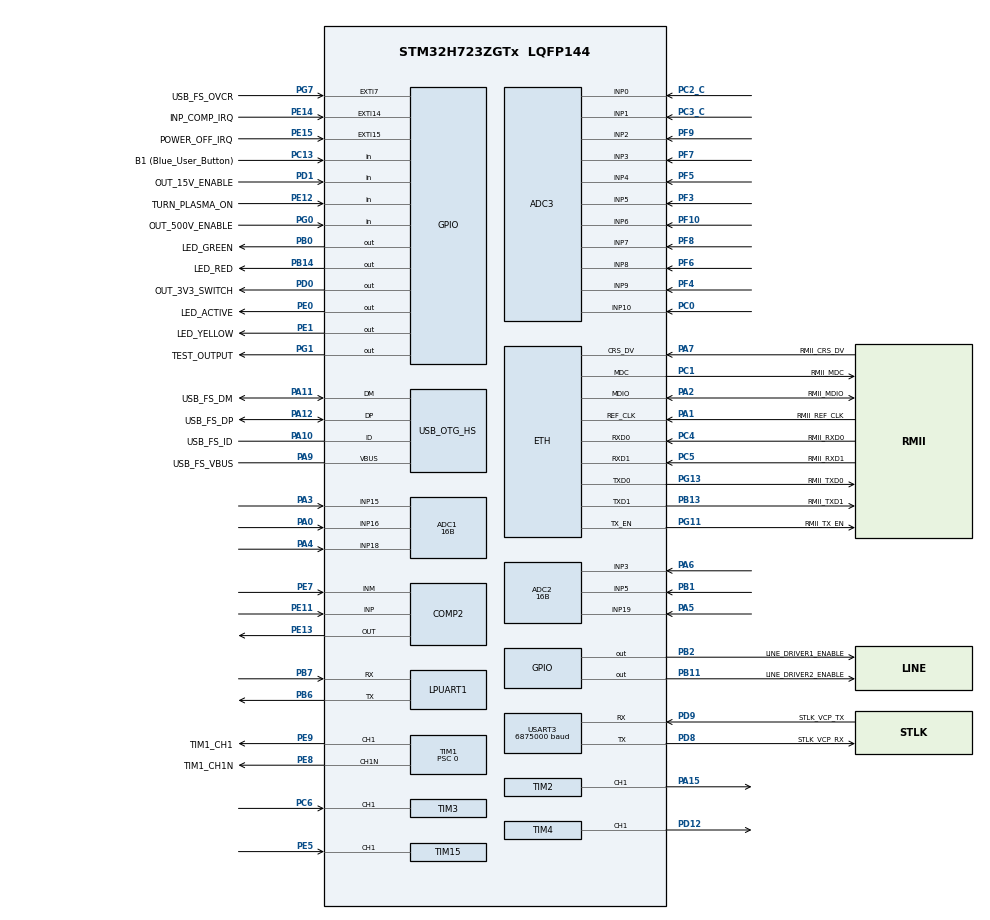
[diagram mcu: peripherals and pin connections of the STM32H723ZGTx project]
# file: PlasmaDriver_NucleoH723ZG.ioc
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ADC1.Channel-11\#ChannelRegularConversion=ADC_CHANNEL_16
ADC1.Channel-6\#ChannelRegularConversion=ADC_CHANNEL_15
ADC1.Channel-7\#ChannelRegularConversion=ADC_CHANNEL_18
ADC1.ContinuousConvMode=ENABLE
ADC1.ConversionDataManagement=ADC_CONVERSIONDATA_DMA_ONESHOT
ADC1.DMAAccessModeView=ENABLE
ADC1.DiscontinuousConvMode=DISABLE
ADC1.EOCSelection=ADC_EOC_SEQ_CONV
ADC1.ExternalTrigConv=ADC_EXTERNALTRIG_T1_CC1
ADC1.LowPowerAutoWait=DISABLE
ADC1.Mode=ADC_DUALMODE_REGSIMULT
ADC1.NbrOfConversion=3
ADC1.NbrOfConversionFlag=1
ADC1.OffsetNumber-11\#ChannelRegularConversion=ADC_OFFSET_NONE
ADC1.OffsetNumber-6\#ChannelRegularConversion=ADC_OFFSET_NONE
ADC1.OffsetNumber-7\#ChannelRegularConversion=ADC_OFFSET_NONE
ADC1.OffsetSignedSaturation-11\#ChannelRegularConversion=DISABLE
ADC1.OffsetSignedSaturation-6\#ChannelRegularConversion=DISABLE
ADC1.OffsetSignedSaturation-7\#ChannelRegularConversion=DISABLE
ADC1.Rank-11\#ChannelRegularConversion=3
ADC1.Rank-6\#ChannelRegularConversion=1
ADC1.Rank-7\#ChannelRegularConversion=2
ADC1.Resolution=ADC_RESOLUTION_16B
ADC1.SamplingTime-11\#ChannelRegularConversion=ADC_SAMPLETIME_8CYCLES_5
ADC1.SamplingTime-6\#ChannelRegularConversion=ADC_SAMPLETIME_8CYCLES_5
ADC1.SamplingTime-7\#ChannelRegularConversion=ADC_SAMPLETIME_8CYCLES_5
ADC1.TwoSamplingDelay=ADC_TWOSAMPLINGDELAY_1CYCLE
ADC1.master=1
ADC2.Channel-0\#ChannelRegularConversion=ADC_CHANNEL_3
ADC2.Channel-1\#ChannelRegularConversion=ADC_CHANNEL_19
ADC2.Channel-3\#ChannelRegularConversion=ADC_CHANNEL_5
ADC2.ClockPrescaler=ADC_CLOCK_ASYNC_DIV1
ADC2.ContinuousConvMode=ENABLE
ADC2.ConversionDataManagement=ADC_CONVERSIONDATA_DR
ADC2.DMAAccessModeView=ENABLE
ADC2.EOCSelection=ADC_EOC_SEQ_CONV
ADC2.EnableAnalogWatchDog1=true
ADC2.Mode=ADC_DUALMODE_REGSIMULT
ADC2.NbrOfConversion=3
ADC2.NbrOfConversionFlag=1
ADC2.OffsetNumber-0\#ChannelRegularConversion=ADC_OFFSET_NONE
ADC2.OffsetNumber-1\#ChannelRegularConversion=ADC_OFFSET_NONE
ADC2.OffsetNumber-3\#ChannelRegularConversion=ADC_OFFSET_NONE
ADC2.OffsetSignedSaturation-0\#ChannelRegularConversion=DISABLE
ADC2.OffsetSignedSaturation-1\#ChannelRegularConversion=DISABLE
ADC2.OffsetSignedSaturation-3\#ChannelRegularConversion=DISABLE
ADC2.Rank-0\#ChannelRegularConversion=1
ADC2.Rank-1\#ChannelRegularConversion=2
ADC2.Rank-3\#ChannelRegularConversion=3
ADC2.Resolution=ADC_RESOLUTION_16B
ADC2.SamplingTime-0\#ChannelRegularConversion=ADC_SAMPLETIME_8CYCLES_5
ADC2.SamplingTime-1\#ChannelRegularConversion=ADC_SAMPLETIME_8CYCLES_5
ADC2.SamplingTime-3\#ChannelRegularConversion=ADC_SAMPLETIME_8CYCLES_5
ADC2.WatchdogChannel=ADC_CHANNEL_3
ADC3.Channel-0\#ChannelRegularConversion=ADC_CHANNEL_0
ADC3.Channel-1\#ChannelRegularConversion=ADC_CHANNEL_1
ADC3.Channel-11\#ChannelRegularConversion=ADC_CHANNEL_10
ADC3.Channel-2\#ChannelRegularConversion=ADC_CHANNEL_2
ADC3.Channel-3\#ChannelRegularConversion=ADC_CHANNEL_3
ADC3.Channel-4\#ChannelRegularConversion=ADC_CHANNEL_4
ADC3.Channel-5\#ChannelRegularConversion=ADC_CHANNEL_5
ADC3.Channel-6\#ChannelRegularConversion=ADC_CHANNEL_6
ADC3.Channel-7\#ChannelRegularConversion=ADC_CHANNEL_7
ADC3.Channel-8\#ChannelRegularConversion=ADC_CHANNEL_8
ADC3.Channel-9\#ChannelRegularConversion=ADC_CHANNEL_9
ADC3.ClockPrescaler=ADC_CLOCK_ASYNC_DIV1
ADC3.ContinuousConvMode=DISABLE
ADC3.ConversionDataManagement=ADC_CONVERSIONDATA_DMA_ONESHOT
ADC3.DMAContinuousRequests=ENABLE
ADC3.EOCSelection=ADC_EOC_SEQ_CONV
ADC3.Mode=ADC_DUALMODE_REGSIMULT
ADC3.NbrOfConversion=11
ADC3.NbrOfConversionFlag=1
ADC3.OffsetNumber-0\#ChannelRegularConversion=ADC_OFFSET_NONE
ADC3.OffsetNumber-1\#ChannelRegularConversion=ADC_OFFSET_NONE
ADC3.OffsetNumber-11\#ChannelRegularConversion=ADC_OFFSET_NONE
ADC3.OffsetNumber-2\#ChannelRegularConversion=ADC_OFFSET_NONE
ADC3.OffsetNumber-3\#ChannelRegularConversion=ADC_OFFSET_NONE
ADC3.OffsetNumber-4\#ChannelRegularConversion=ADC_OFFSET_NONE
ADC3.OffsetNumber-5\#ChannelRegularConversion=ADC_OFFSET_NONE
ADC3.OffsetNumber-6\#ChannelRegularConversion=ADC_OFFSET_NONE
ADC3.OffsetNumber-7\#ChannelRegularConversion=ADC_OFFSET_NONE
ADC3.OffsetNumber-8\#ChannelRegularConversion=ADC_OFFSET_NONE
ADC3.OffsetNumber-9\#ChannelRegularConversion=ADC_OFFSET_NONE
ADC3.OffsetSign-0\#ChannelRegularConversion=ADC3_OFFSET_SIGN_NEGATIVE
ADC3.OffsetSign-1\#ChannelRegularConversion=ADC3_OFFSET_SIGN_NEGATIVE
ADC3.OffsetSign-11\#ChannelRegularConversion=ADC3_OFFSET_SIGN_NEGATIVE
ADC3.OffsetSign-2\#ChannelRegularConversion=ADC3_OFFSET_SIGN_NEGATIVE
ADC3.OffsetSign-3\#ChannelRegularConversion=ADC3_OFFSET_SIGN_NEGATIVE
ADC3.OffsetSign-4\#ChannelRegularConversion=ADC3_OFFSET_SIGN_NEGATIVE
ADC3.OffsetSign-5\#ChannelRegularConversion=ADC3_OFFSET_SIGN_NEGATIVE
ADC3.OffsetSign-6\#ChannelRegularConversion=ADC3_OFFSET_SIGN_NEGATIVE
ADC3.OffsetSign-7\#ChannelRegularConversion=ADC3_OFFSET_SIGN_NEGATIVE
ADC3.OffsetSign-8\#ChannelRegularConversion=ADC3_OFFSET_SIGN_NEGATIVE
ADC3.OffsetSign-9\#ChannelRegularConversion=ADC3_OFFSET_SIGN_NEGATIVE
ADC3.Rank-0\#ChannelRegularConversion=1
ADC3.Rank-1\#ChannelRegularConversion=2
ADC3.Rank-11\#ChannelRegularConversion=11
ADC3.Rank-2\#ChannelRegularConversion=3
ADC3.Rank-3\#ChannelRegularConversion=4
ADC3.Rank-4\#ChannelRegularConversion=5
ADC3.Rank-5\#ChannelRegularConversion=6
ADC3.Rank-6\#ChannelRegularConversion=7
ADC3.Rank-7\#ChannelRegularConversion=8
ADC3.Rank-8\#ChannelRegularConversion=9
ADC3.Rank-9\#ChannelRegularConversion=10
ADC3.SamplingTime-0\#ChannelRegularConversion=ADC3_SAMPLETIME_6CYCLES_5
ADC3.SamplingTime-1\#ChannelRegularConversion=ADC3_SAMPLETIME_6CYCLES_5
ADC3.SamplingTime-11\#ChannelRegularConversion=ADC3_SAMPLETIME_6CYCLES_5
ADC3.SamplingTime-2\#ChannelRegularConversion=ADC3_SAMPLETIME_6CYCLES_5
ADC3.SamplingTime-3\#ChannelRegularConversion=ADC3_SAMPLETIME_6CYCLES_5
ADC3.SamplingTime-4\#ChannelRegularConversion=ADC3_SAMPLETIME_6CYCLES_5
ADC3.SamplingTime-5\#ChannelRegularConversion=ADC3_SAMPLETIME_6CYCLES_5
ADC3.SamplingTime-6\#ChannelRegularConversion=ADC3_SAMPLETIME_6CYCLES_5
ADC3.SamplingTime-7\#ChannelRegularConversion=ADC3_SAMPLETIME_6CYCLES_5
ADC3.SamplingTime-8\#ChannelRegularConversion=ADC3_SAMPLETIME_6CYCLES_5
ADC3.SamplingTime-9\#ChannelRegularConversion=ADC3_SAMPLETIME_6CYCLES_5
CORTEX_M7.CPU_DCache=Disabled
CORTEX_M7.CPU_ICache=Disabled
Dma.ADC1.1.Direction=DMA_PERIPH_TO_MEMORY
Dma.ADC1.1.EventEnable=DISABLE
Dma.ADC1.1.FIFOMode=DMA_FIFOMODE_DISABLE
Dma.ADC1.1.Instance=DMA1_Stream2
Dma.ADC1.1.MemDataAlignment=DMA_MDATAALIGN_WORD
Dma.ADC1.1.MemInc=DMA_MINC_ENABLE
Dma.ADC1.1.Mode=DMA_NORMAL
Dma.ADC1.1.PeriphDataAlignment=DMA_PDATAALIGN_WORD
Dma.ADC1.1.PeriphInc=DMA_PINC_DISABLE
Dma.ADC1.1.Polarity=HAL_DMAMUX_REQ_GEN_RISING
Dma.ADC1.1.Priority=DMA_PRIORITY_HIGH
Dma.ADC1.1.RequestNumber=1
Dma.ADC1.1.SignalID=NONE
Dma.ADC1.1.SyncEnable=DISABLE
Dma.ADC1.1.SyncPolarity=HAL_DMAMUX_SYNC_NO_EVENT
Dma.ADC1.1.SyncRequestNumber=1
Dma.ADC1.1.SyncSignalID=NONE
Dma.ADC3.0.Direction=DMA_PERIPH_TO_MEMORY
Dma.ADC3.0.EventEnable=DISABLE
Dma.ADC3.0.FIFOMode=DMA_FIFOMODE_DISABLE
Dma.ADC3.0.Instance=DMA1_Stream1
Dma.ADC3.0.MemDataAlignment=DMA_MDATAALIGN_HALFWORD
Dma.ADC3.0.MemInc=DMA_MINC_ENABLE
Dma.ADC3.0.Mode=DMA_NORMAL
Dma.ADC3.0.PeriphDataAlignment=DMA_PDATAALIGN_HALFWORD
Dma.ADC3.0.PeriphInc=DMA_PINC_DISABLE
Dma.ADC3.0.Polarity=HAL_DMAMUX_REQ_GEN_RISING
Dma.ADC3.0.Priority=DMA_PRIORITY_LOW
Dma.ADC3.0.RequestNumber=1
Dma.ADC3.0.SignalID=NONE
Dma.ADC3.0.SyncEnable=DISABLE
Dma.ADC3.0.SyncPolarity=HAL_DMAMUX_SYNC_NO_EVENT
Dma.ADC3.0.SyncRequestNumber=1
Dma.ADC3.0.SyncSignalID=NONE
Dma.Request0=ADC3
Dma.Request1=ADC1
ETH.MediaInterface=HAL_ETH_RMII_MODE
Mcu.Family=STM32H7
Mcu.Name=STM32H723ZGTx
Mcu.Package=LQFP144
NVIC.ADC_IRQn=true\:0\:0\:false\:false\:true\:true\:true\:true
NVIC.DMA1_Stream1_IRQn=true\:0\:0\:false\:false\:true\:false\:true\:true
NVIC.DMA1_Stream2_IRQn=true\:0\:0\:false\:false\:true\:false\:true\:true
NVIC.EXTI15_10_IRQn=true\:0\:0\:false\:false\:true\:true\:true\:true
NVIC.PriorityGroup=NVIC_PRIORITYGROUP_4
NVIC.USART3_IRQn=true\:0\:0\:false\:false\:true\:true\:true\:true
PA0.Mode=IN16-Single-Ended
PA0.Signal=ADC1_INP16
PA1.GPIO_Label=RMII_REF_CLK
PA1.Mode=RMII
PA1.Signal=ETH_REF_CLK
PA10.GPIO_Label=USB_FS_ID
PA10.Mode=OTG/Dual-Role-Device-FS
PA10.Signal=USB_OTG_HS_ID
PA11.GPIO_Label=USB_FS_DM
PA11.Mode=OTG/Dual-Role-Device-FS
PA11.Signal=USB_OTG_HS_DM
PA12.GPIO_Label=USB_FS_DP
PA12.Mode=OTG/Dual-Role-Device-FS
PA12.Signal=USB_OTG_HS_DP
PA13(JTMS/SWDIO).GPIO_Label=SWDIO
PA13(JTMS/SWDIO).Mode=Trace_Asynchronous_SW
PA13(JTMS/SWDIO).Signal=DEBUG_JTMS-SWDIO
PA14(JTCK/SWCLK).GPIO_Label=SWCLK
PA14(JTCK/SWCLK).Mode=Trace_Asynchronous_SW
PA14(JTCK/SWCLK).Signal=DEBUG_JTCK-SWCLK
PA15(JTDI).GPIO_ModeDefaultPP=GPIO_MODE_AF_OD
PA15(JTDI).GPIO_PuPd=GPIO_NOPULL
PA15(JTDI).Signal=S_TIM2_CH1_ETR
PA2.GPIO_Label=RMII_MDIO
PA2.Mode=RMII
PA2.Signal=ETH_MDIO
PA3.Signal=ADCx_INP15
PA4.Signal=ADCx_INP18
PA5.Signal=ADCx_INP19
PA6.Signal=ADCx_INP3
PA7.GPIO_Label=RMII_CRS_DV
PA7.Mode=RMII
PA7.Signal=ETH_CRS_DV
PA9.GPIO_Label=USB_FS_VBUS
PA9.Mode=Activate_VBUS_FS
PA9.Signal=USB_OTG_HS_VBUS
PB0.GPIO_Label=LED_GREEN
PB0.PinState=GPIO_PIN_SET
PB0.Signal=GPIO_Output
PB1.Signal=ADCx_INP5
PB11.GPIO_Label=LINE_DRIVER2_ENABLE
PB11.PinState=GPIO_PIN_SET
PB11.Signal=GPIO_Output
PB13.GPIO_Label=RMII_TXD1
PB13.Mode=RMII
PB13.Signal=ETH_TXD1
PB14.GPIO_Label=LED_RED
PB14.Signal=GPIO_Output
PB2.GPIO_Label=LINE_DRIVER1_ENABLE
PB2.PinState=GPIO_PIN_SET
PB2.Signal=GPIO_Output
PB3(JTDO/TRACESWO).GPIO_Label=SWO
PB3(JTDO/TRACESWO).Mode=Trace_Asynchronous_SW
PB3(JTDO/TRACESWO).Signal=DEBUG_JTDO-SWO
PB6.Mode=Asynchronous
PB6.Signal=LPUART1_TX
PB7.Mode=Asynchronous
PB7.Signal=LPUART1_RX
PC0.Signal=ADCx_INP10
PC1.GPIO_Label=RMII_MDC
PC1.Mode=RMII
PC1.Signal=ETH_MDC
PC13.GPIO_Label=B1 (Blue_User_Button)
PC13.Signal=GPIO_Input
PC14-OSC32_IN.Mode=LSE-External-Oscillator
PC14-OSC32_IN.Signal=RCC_OSC32_IN
PC15-OSC32_OUT.Mode=LSE-External-Oscillator
PC15-OSC32_OUT.Signal=RCC_OSC32_OUT
PC2_C.Mode=IN0-Single-Ended
PC2_C.Signal=ADC3_INP0
PC3_C.Mode=IN1-Single-Ended
PC3_C.Signal=ADC3_INP1
PC4.GPIO_Label=RMII_RXD0
PC4.Mode=RMII
PC4.Signal=ETH_RXD0
PC5.GPIO_Label=RMII_RXD1
PC5.Mode=RMII
PC5.Signal=ETH_RXD1
PC6.GPIO_ModeDefaultPP=GPIO_MODE_AF_PP
PC6.GPIO_PuPd=GPIO_PULLUP
PC6.Signal=S_TIM3_CH1
PD0.GPIO_Label=OUT_3V3_SWITCH
PD0.PinState=GPIO_PIN_SET
PD0.Signal=GPIO_Output
PD1.GPIO_Label=OUT_15V_ENABLE
PD1.Signal=GPIO_Input
PD12.GPIO_ModeDefaultPP=GPIO_MODE_AF_OD
PD12.Signal=S_TIM4_CH1
PD8.GPIO_Label=STLK_VCP_RX
PD8.Mode=Asynchronous
PD8.Signal=USART3_TX
PD9.GPIO_Label=STLK_VCP_TX
PD9.Mode=Asynchronous
PD9.Signal=USART3_RX
PE0.GPIO_Label=LED_ACTIVE
PE0.PinState=GPIO_PIN_SET
PE0.Signal=GPIO_Output
PE1.GPIO_Label=LED_YELLOW
PE1.Signal=GPIO_Output
PE11.Mode=INP
PE11.Signal=COMP2_INP
PE12.GPIO_Label=TURN_PLASMA_ON
PE12.Signal=GPIO_Input
PE13.Mode=ExternalOutput
PE13.Signal=COMP2_OUT
PE14.GPIO_Label=INP_COMP_IRQ
PE14.GPIO_ModeDefaultEXTI=GPIO_MODE_IT_RISING
PE14.Signal=GPXTI14
PE15.GPIO_Label=POWER_OFF_IRQ
PE15.GPIO_ModeDefaultEXTI=GPIO_MODE_IT_FALLING
PE15.Signal=GPXTI15
PE5.GPIO_PuPd=GPIO_PULLUP
PE5.Signal=S_TIM15_CH1
PE7.Mode=INM
PE7.Signal=COMP2_INM
PE8.GPIO_Label=TIM1_CH1N
PE8.GPIO_ModeDefaultPP=GPIO_MODE_AF_PP
PE8.Mode=PWM Generation1 CH1 CH1N
PE8.Signal=TIM1_CH1N
PE9.GPIO_Label=TIM1_CH1
PE9.Signal=S_TIM1_CH1
PF10.Mode=IN6-Single-Ended
PF10.Signal=ADC3_INP6
PF3.Mode=IN5-Single-Ended
PF3.Signal=ADC3_INP5
PF4.Mode=IN9-Single-Ended
PF4.Signal=ADC3_INP9
PF5.Mode=IN4-Single-Ended
PF5.Signal=ADC3_INP4
PF6.Mode=IN8-Single-Ended
PF6.Signal=ADC3_INP8
PF7.Mode=IN3-Single-Ended
PF7.Signal=ADC3_INP3
PF8.Mode=IN7-Single-Ended
PF8.Signal=ADC3_INP7
PF9.Mode=IN2-Single-Ended
PF9.Signal=ADC3_INP2
PG0.GPIO_Label=OUT_500V_ENABLE
PG0.Signal=GPIO_Input
PG1.GPIO_Label=TEST_OUTPUT
PG1.Signal=GPIO_Output
PG11.GPIO_Label=RMII_TX_EN
PG11.Mode=RMII
PG11.Signal=ETH_TX_EN
PG13.GPIO_Label=RMII_TXD0
PG13.Mode=RMII
PG13.Signal=ETH_TXD0
PG7.GPIO_Label=USB_FS_OVCR
PG7.Signal=GPXTI7
PH0-OSC_IN.GPIO_Label=MCO
PH0-OSC_IN.Mode=HSE-External-Clock-Source
PH0-OSC_IN.Signal=RCC_OSC_IN
PH1-OSC_OUT.Signal=RCC_OSC_OUT
ProjectManager.HeapSize=0x200
ProjectManager.StackSize=0x400
ProjectManager.TargetToolchain=STM32CubeIDE
RCC.ADCFreq_Value=96000000
RCC.APB1Freq_Value=137500000
RCC.APB2Freq_Value=17187500
RCC.APB3Freq_Value=137500000
RCC.APB4Freq_Value=137500000
RCC.CortexFreq_Value=550000000
RCC.D1PPRE=RCC_APB3_DIV2
RCC.D2PPRE1=RCC_APB1_DIV2
RCC.D2PPRE2=RCC_APB2_DIV16
RCC.D3PPRE=RCC_APB4_DIV2
RCC.DIVM1=4
RCC.DIVM2=1
RCC.DIVN1=275
RCC.DIVN2=24
RCC.DIVP1=1
RCC.DIVQ1=4
RCC.HCLKFreq_Value=275000000
RCC.HPRE=RCC_HCLK_DIV2
RCC.HSE_VALUE=8000000
RCC.PLLFRACN=0
RCC.PLLSourceVirtual=RCC_PLLSOURCE_HSE
RCC.SYSCLKFreq_VALUE=550000000
RCC.SYSCLKSource=RCC_SYSCLKSOURCE_PLLCLK
RCC.USBCLockSelection=RCC_USBCLKSOURCE_HSI48
RCC.USBFreq_Value=48000000
SH.ADCx_INP10.0=ADC3_INP10,IN10-Single-Ended
SH.ADCx_INP15.0=ADC1_INP15,IN15-Single-Ended
SH.ADCx_INP18.0=ADC1_INP18,IN18-Single-Ended
SH.ADCx_INP19.0=ADC2_INP19,IN19-Single-Ended
SH.ADCx_INP3.0=ADC2_INP3,IN3-Single-Ended
SH.ADCx_INP5.0=ADC2_INP5,IN5-Single-Ended
SH.S_TIM15_CH1.0=TIM15_CH1,Input_Capture1_from_TI1
SH.S_TIM1_CH1.0=TIM1_CH1,PWM Generation1 CH1 CH1N
SH.S_TIM2_CH1_ETR.0=TIM2_CH1,PWM Generation1 CH1
SH.S_TIM3_CH1.0=TIM3_CH1,Input_Capture1_from_TI1
SH.S_TIM4_CH1.0=TIM4_CH1,PWM Generation1 CH1
TIM1.Channel-PWM\ Generation1\ CH1\ CH1N=TIM_CHANNEL_1
TIM1.DeadTime=0xFF
TIM1.OCIdleState_1=TIM_OCIDLESTATE_SET
TIM1.OCNIdleState_1=TIM_OCNIDLESTATE_SET
TIM1.OCNPolarity_1=TIM_OCNPOLARITY_LOW
TIM1.OCPolarity_1=TIM_OCPOLARITY_LOW
TIM1.OffStateIDLEMode=TIM_OSSI_DISABLE
TIM1.OffStateRunMode=TIM_OSSR_DISABLE
TIM1.Period=3240
TIM1.Prescaler=0
TIM1.Pulse-PWM\ Generation1\ CH1\ CH1N=1620
TIM15.Channel-Input_Capture1_from_TI1=TIM_CHANNEL_1
TIM2.Channel-PWM\ Generation1\ CH1=TIM_CHANNEL_1
TIM24.AutoReloadPreload=TIM_AUTORELOAD_PRELOAD_ENABLE
TIM24.Prescaler=275 - 1
TIM3.Channel-Input_Capture1_from_TI1=TIM_CHANNEL_1
TIM4.Channel-PWM\ Generation1\ CH1=TIM_CHANNEL_1
USART3.BaudRate=6875000
USART3.VirtualMode-Asynchronous=VM_ASYNC
VP_TIM24_VS_ClockSourceINT.Mode=Internal
board=NUCLEO-H723ZG

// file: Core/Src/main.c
/* USER CODE BEGIN Header */
/**
  ******************************************************************************
  * @file           : main.c
  * @brief          : Main program body
  ******************************************************************************
  * @attention
  *
  * Copyright (c) 2023 STMicroelectronics.
  * All rights reserved.
  *
  * This software is licensed under terms that can be found in the LICENSE file
  * in the root directory of this software component.
  * If no LICENSE file comes with this software, it is provided AS-IS.
  *
  ******************************************************************************
  */
/* USER CODE END Header */
#include "main.h"
#include "string.h"

#if defined ( __ICCARM__ ) /*!< IAR Compiler */
#pragma location=0x30000000
ETH_DMADescTypeDef  DMARxDscrTab[ETH_RX_DESC_CNT]; /* Ethernet Rx DMA Descriptors */
#pragma location=0x30000200
ETH_DMADescTypeDef  DMATxDscrTab[ETH_TX_DESC_CNT]; /* Ethernet Tx DMA Descriptors */

#elif defined ( __CC_ARM )  /* MDK ARM Compiler */

__attribute__((at(0x30000000))) ETH_DMADescTypeDef  DMARxDscrTab[ETH_RX_DESC_CNT]; /* Ethernet Rx DMA Descriptors */
__attribute__((at(0x30000200))) ETH_DMADescTypeDef  DMATxDscrTab[ETH_TX_DESC_CNT]; /* Ethernet Tx DMA Descriptors */

#elif defined ( __GNUC__ ) /* GNU Compiler */
ETH_DMADescTypeDef DMARxDscrTab[ETH_RX_DESC_CNT] __attribute__((section(".RxDecripSection"))); /* Ethernet Rx DMA Descriptors */
ETH_DMADescTypeDef DMATxDscrTab[ETH_TX_DESC_CNT] __attribute__((section(".TxDecripSection")));   /* Ethernet Tx DMA Descriptors */

#endif

ETH_TxPacketConfig TxConfig;

ADC_HandleTypeDef hadc1;
ADC_HandleTypeDef hadc2;
ADC_HandleTypeDef hadc3;
DMA_HandleTypeDef hdma_adc1;
DMA_HandleTypeDef hdma_adc3;

COMP_HandleTypeDef hcomp2;

ETH_HandleTypeDef heth;

UART_HandleTypeDef hlpuart1;
UART_HandleTypeDef huart3;

TIM_HandleTypeDef htim1;
TIM_HandleTypeDef htim2;
TIM_HandleTypeDef htim3;
TIM_HandleTypeDef htim4;
TIM_HandleTypeDef htim15;
TIM_HandleTypeDef htim24;

void SystemClock_Config(void);
void PeriphCommonClock_Config(void);
static void MX_GPIO_Init(void);
static void MX_DMA_Init(void);
static void MX_TIM1_Init(void);
static void MX_ETH_Init(void);
static void MX_ADC2_Init(void);
static void MX_USB_OTG_HS_USB_Init(void);
static void MX_ADC3_Init(void);
static void MX_USART3_UART_Init(void);
static void MX_ADC1_Init(void);
static void MX_COMP2_Init(void);
static void MX_TIM2_Init(void);
static void MX_LPUART1_UART_Init(void);
static void MX_TIM3_Init(void);
static void MX_TIM4_Init(void);
static void MX_TIM15_Init(void);
static void MX_TIM24_Init(void);
/* USER CODE BEGIN PFP */
void PlasmaDriverInit(void);
void PlasmaDoTask(void);
/* USER CODE END PFP */

int main(void)
{

  /* MCU Configuration--------------------------------------------------------*/

  /* Reset of all peripherals, Initializes the Flash interface and the Systick. */
  HAL_Init();

  /* Configure the system clock */
  SystemClock_Config();

/* Configure the peripherals common clocks */
  PeriphCommonClock_Config();

  /* Initialize all configured peripherals */
  MX_GPIO_Init();
  MX_DMA_Init();
  MX_TIM1_Init();
  MX_ETH_Init();
  MX_ADC2_Init();
  MX_USB_OTG_HS_USB_Init();
  MX_ADC3_Init();
  MX_USART3_UART_Init();
  MX_ADC1_Init();
  MX_COMP2_Init();
  MX_TIM2_Init();
  MX_LPUART1_UART_Init();
  MX_TIM3_Init();
  MX_TIM4_Init();
  MX_TIM15_Init();
  MX_TIM24_Init();

  /* Infinite loop */
  /* USER CODE BEGIN WHILE */
  PlasmaDriverInit();  			//Initialize plasma driver

  while (1)
  {
	PlasmaDoTask();     	    //Handle plasma driver task
    /* USER CODE END WHILE */

  }
}

void SystemClock_Config(void)
{
  RCC_OscInitTypeDef RCC_OscInitStruct = {0};
  RCC_ClkInitTypeDef RCC_ClkInitStruct = {0};

  /** Supply configuration update enable
  */
  HAL_PWREx_ConfigSupply(PWR_LDO_SUPPLY);

  /** Configure the main internal regulator output voltage
  */
  __HAL_PWR_VOLTAGESCALING_CONFIG(PWR_REGULATOR_VOLTAGE_SCALE0);

  while(!__HAL_PWR_GET_FLAG(PWR_FLAG_VOSRDY)) {}

  /** Initializes the RCC Oscillators according to the specified parameters
  * in the RCC_OscInitTypeDef structure.
  */
  RCC_OscInitStruct.OscillatorType = RCC_OSCILLATORTYPE_HSI48|RCC_OSCILLATORTYPE_HSE;
  RCC_OscInitStruct.HSEState = RCC_HSE_BYPASS;
  RCC_OscInitStruct.HSI48State = RCC_HSI48_ON;
  RCC_OscInitStruct.PLL.PLLState = RCC_PLL_ON;
  RCC_OscInitStruct.PLL.PLLSource = RCC_PLLSOURCE_HSE;
  RCC_OscInitStruct.PLL.PLLM = 4;
  RCC_OscInitStruct.PLL.PLLN = 275;
  RCC_OscInitStruct.PLL.PLLP = 1;
  RCC_OscInitStruct.PLL.PLLQ = 4;
  RCC_OscInitStruct.PLL.PLLR = 2;
  RCC_OscInitStruct.PLL.PLLRGE = RCC_PLL1VCIRANGE_1;
  RCC_OscInitStruct.PLL.PLLVCOSEL = RCC_PLL1VCOWIDE;
  RCC_OscInitStruct.PLL.PLLFRACN = 0;
  if (HAL_RCC_OscConfig(&RCC_OscInitStruct) != HAL_OK)
  {
    Error_Handler();
  }

  /** Initializes the CPU, AHB and APB buses clocks
  */
  RCC_ClkInitStruct.ClockType = RCC_CLOCKTYPE_HCLK|RCC_CLOCKTYPE_SYSCLK
                              |RCC_CLOCKTYPE_PCLK1|RCC_CLOCKTYPE_PCLK2
                              |RCC_CLOCKTYPE_D3PCLK1|RCC_CLOCKTYPE_D1PCLK1;
  RCC_ClkInitStruct.SYSCLKSource = RCC_SYSCLKSOURCE_PLLCLK;
  RCC_ClkInitStruct.SYSCLKDivider = RCC_SYSCLK_DIV1;
  RCC_ClkInitStruct.AHBCLKDivider = RCC_HCLK_DIV2;
  RCC_ClkInitStruct.APB3CLKDivider = RCC_APB3_DIV2;
  RCC_ClkInitStruct.APB1CLKDivider = RCC_APB1_DIV2;
  RCC_ClkInitStruct.APB2CLKDivider = RCC_APB2_DIV16;
  RCC_ClkInitStruct.APB4CLKDivider = RCC_APB4_DIV2;

  if (HAL_RCC_ClockConfig(&RCC_ClkInitStruct, FLASH_LATENCY_3) != HAL_OK)
  {
    Error_Handler();
  }
}

void PeriphCommonClock_Config(void)
{
  RCC_PeriphCLKInitTypeDef PeriphClkInitStruct = {0};

  /** Initializes the peripherals clock
  */
  PeriphClkInitStruct.PeriphClockSelection = RCC_PERIPHCLK_ADC;
  PeriphClkInitStruct.PLL2.PLL2M = 1;
  PeriphClkInitStruct.PLL2.PLL2N = 24;
  PeriphClkInitStruct.PLL2.PLL2P = 2;
  PeriphClkInitStruct.PLL2.PLL2Q = 2;
  PeriphClkInitStruct.PLL2.PLL2R = 2;
  PeriphClkInitStruct.PLL2.PLL2RGE = RCC_PLL2VCIRANGE_3;
  PeriphClkInitStruct.PLL2.PLL2VCOSEL = RCC_PLL2VCOWIDE;
  PeriphClkInitStruct.PLL2.PLL2FRACN = 0;
  PeriphClkInitStruct.AdcClockSelection = RCC_ADCCLKSOURCE_PLL2;
  if (HAL_RCCEx_PeriphCLKConfig(&PeriphClkInitStruct) != HAL_OK)
  {
    Error_Handler();
  }
}

static void MX_ADC1_Init(void)
{

  ADC_MultiModeTypeDef multimode = {0};
  ADC_ChannelConfTypeDef sConfig = {0};

  /** Common config
  */
  hadc1.Instance = ADC1;
  hadc1.Init.ClockPrescaler = ADC_CLOCK_ASYNC_DIV1;
  hadc1.Init.Resolution = ADC_RESOLUTION_16B;
  hadc1.Init.ScanConvMode = ADC_SCAN_ENABLE;
  hadc1.Init.EOCSelection = ADC_EOC_SEQ_CONV;
  hadc1.Init.LowPowerAutoWait = DISABLE;
  hadc1.Init.ContinuousConvMode = ENABLE;
  hadc1.Init.NbrOfConversion = 3;
  hadc1.Init.DiscontinuousConvMode = DISABLE;
  hadc1.Init.ExternalTrigConv = ADC_EXTERNALTRIG_T1_CC1;
  hadc1.Init.ExternalTrigConvEdge = ADC_EXTERNALTRIGCONVEDGE_RISING;
  hadc1.Init.ConversionDataManagement = ADC_CONVERSIONDATA_DMA_ONESHOT;
  hadc1.Init.Overrun = ADC_OVR_DATA_PRESERVED;
  hadc1.Init.LeftBitShift = ADC_LEFTBITSHIFT_NONE;
  hadc1.Init.OversamplingMode = DISABLE;
  if (HAL_ADC_Init(&hadc1) != HAL_OK)
  {
    Error_Handler();
  }

  /** Configure the ADC multi-mode
  */
  multimode.Mode = ADC_DUALMODE_REGSIMULT;
  multimode.DualModeData = ADC_DUALMODEDATAFORMAT_32_10_BITS;
  multimode.TwoSamplingDelay = ADC_TWOSAMPLINGDELAY_1CYCLE;
  if (HAL_ADCEx_MultiModeConfigChannel(&hadc1, &multimode) != HAL_OK)
  {
    Error_Handler();
  }

  /** Configure Regular Channel
  */
  sConfig.Channel = ADC_CHANNEL_15;
  sConfig.Rank = ADC_REGULAR_RANK_1;
  sConfig.SamplingTime = ADC_SAMPLETIME_2CYCLES_5;
  sConfig.SingleDiff = ADC_SINGLE_ENDED;
  sConfig.OffsetNumber = ADC_OFFSET_NONE;
  sConfig.Offset = 0;
  sConfig.OffsetSignedSaturation = DISABLE;
  if (HAL_ADC_ConfigChannel(&hadc1, &sConfig) != HAL_OK)
  {
    Error_Handler();
  }

  /** Configure Regular Channel
  */
  sConfig.Channel = ADC_CHANNEL_18;
  sConfig.Rank = ADC_REGULAR_RANK_2;
  if (HAL_ADC_ConfigChannel(&hadc1, &sConfig) != HAL_OK)
  {
    Error_Handler();
  }

  /** Configure Regular Channel
  */
  sConfig.Channel = ADC_CHANNEL_16;
  sConfig.Rank = ADC_REGULAR_RANK_3;
  if (HAL_ADC_ConfigChannel(&hadc1, &sConfig) != HAL_OK)
  {
    Error_Handler();
  }

}

static void MX_ADC2_Init(void)
{

  ADC_AnalogWDGConfTypeDef AnalogWDGConfig = {0};
  ADC_ChannelConfTypeDef sConfig = {0};

  /** Common config
  */
  hadc2.Instance = ADC2;
  hadc2.Init.ClockPrescaler = ADC_CLOCK_ASYNC_DIV1;
  hadc2.Init.Resolution = ADC_RESOLUTION_16B;
  hadc2.Init.ScanConvMode = ADC_SCAN_ENABLE;
  hadc2.Init.EOCSelection = ADC_EOC_SEQ_CONV;
  hadc2.Init.LowPowerAutoWait = DISABLE;
  hadc2.Init.ContinuousConvMode = ENABLE;
  hadc2.Init.NbrOfConversion = 3;
  hadc2.Init.DiscontinuousConvMode = DISABLE;
  hadc2.Init.ConversionDataManagement = ADC_CONVERSIONDATA_DR;
  hadc2.Init.Overrun = ADC_OVR_DATA_PRESERVED;
  hadc2.Init.LeftBitShift = ADC_LEFTBITSHIFT_NONE;
  hadc2.Init.OversamplingMode = DISABLE;
  if (HAL_ADC_Init(&hadc2) != HAL_OK)
  {
    Error_Handler();
  }

  /** Configure Analog WatchDog 1
  */
  AnalogWDGConfig.WatchdogNumber = ADC_ANALOGWATCHDOG_1;
  AnalogWDGConfig.WatchdogMode = ADC_ANALOGWATCHDOG_SINGLE_REG;
  AnalogWDGConfig.Channel = ADC_CHANNEL_3;
  AnalogWDGConfig.ITMode = DISABLE;
  AnalogWDGConfig.HighThreshold = 0;
  AnalogWDGConfig.LowThreshold = 0;
  if (HAL_ADC_AnalogWDGConfig(&hadc2, &AnalogWDGConfig) != HAL_OK)
  {
    Error_Handler();
  }

  /** Configure Regular Channel
  */
  sConfig.Channel = ADC_CHANNEL_3;
  sConfig.Rank = ADC_REGULAR_RANK_1;
  sConfig.SamplingTime = ADC_SAMPLETIME_2CYCLES_5;
  sConfig.SingleDiff = ADC_SINGLE_ENDED;
  sConfig.OffsetNumber = ADC_OFFSET_NONE;
  sConfig.Offset = 0;
  sConfig.OffsetSignedSaturation = DISABLE;
  if (HAL_ADC_ConfigChannel(&hadc2, &sConfig) != HAL_OK)
  {
    Error_Handler();
  }

  /** Configure Regular Channel
  */
  sConfig.Channel = ADC_CHANNEL_19;
  sConfig.Rank = ADC_REGULAR_RANK_2;
  if (HAL_ADC_ConfigChannel(&hadc2, &sConfig) != HAL_OK)
  {
    Error_Handler();
  }

  /** Configure Regular Channel
  */
  sConfig.Channel = ADC_CHANNEL_5;
  sConfig.Rank = ADC_REGULAR_RANK_3;
  if (HAL_ADC_ConfigChannel(&hadc2, &sConfig) != HAL_OK)
  {
    Error_Handler();
  }

}

static void MX_ADC3_Init(void)
{

  ADC_ChannelConfTypeDef sConfig = {0};

  /** Common config
  */
  hadc3.Instance = ADC3;
  hadc3.Init.ClockPrescaler = ADC_CLOCK_ASYNC_DIV1;
  hadc3.Init.Resolution = ADC_RESOLUTION_12B;
  hadc3.Init.DataAlign = ADC3_DATAALIGN_RIGHT;
  hadc3.Init.ScanConvMode = ADC_SCAN_ENABLE;
  hadc3.Init.EOCSelection = ADC_EOC_SEQ_CONV;
  hadc3.Init.LowPowerAutoWait = DISABLE;
  hadc3.Init.ContinuousConvMode = DISABLE;
  hadc3.Init.NbrOfConversion = 11;
  hadc3.Init.DiscontinuousConvMode = DISABLE;
  hadc3.Init.ExternalTrigConv = ADC_SOFTWARE_START;
  hadc3.Init.ExternalTrigConvEdge = ADC_EXTERNALTRIGCONVEDGE_NONE;
  hadc3.Init.DMAContinuousRequests = ENABLE;
  hadc3.Init.SamplingMode = ADC_SAMPLING_MODE_NORMAL;
  hadc3.Init.ConversionDataManagement = ADC_CONVERSIONDATA_DMA_ONESHOT;
  hadc3.Init.Overrun = ADC_OVR_DATA_PRESERVED;
  hadc3.Init.LeftBitShift = ADC_LEFTBITSHIFT_NONE;
  hadc3.Init.OversamplingMode = DISABLE;
  if (HAL_ADC_Init(&hadc3) != HAL_OK)
  {
    Error_Handler();
  }

  /** Configure Regular Channel
  */
  sConfig.Channel = ADC_CHANNEL_0;
  sConfig.Rank = ADC_REGULAR_RANK_1;
  sConfig.SamplingTime = ADC3_SAMPLETIME_6CYCLES_5;
  sConfig.SingleDiff = ADC_SINGLE_ENDED;
  sConfig.OffsetNumber = ADC_OFFSET_NONE;
  sConfig.Offset = 0;
  sConfig.OffsetSign = ADC3_OFFSET_SIGN_NEGATIVE;
  if (HAL_ADC_ConfigChannel(&hadc3, &sConfig) != HAL_OK)
  {
    Error_Handler();
  }

  /** Configure Regular Channel
  */
  sConfig.Channel = ADC_CHANNEL_1;
  sConfig.Rank = ADC_REGULAR_RANK_2;
  if (HAL_ADC_ConfigChannel(&hadc3, &sConfig) != HAL_OK)
  {
    Error_Handler();
  }

  /** Configure Regular Channel
  */
  sConfig.Channel = ADC_CHANNEL_2;
  sConfig.Rank = ADC_REGULAR_RANK_3;
  if (HAL_ADC_ConfigChannel(&hadc3, &sConfig) != HAL_OK)
  {
    Error_Handler();
  }

  /** Configure Regular Channel
  */
  sConfig.Channel = ADC_CHANNEL_3;
  sConfig.Rank = ADC_REGULAR_RANK_4;
  if (HAL_ADC_ConfigChannel(&hadc3, &sConfig) != HAL_OK)
  {
    Error_Handler();
  }

  /** Configure Regular Channel
  */
  sConfig.Channel = ADC_CHANNEL_4;
  sConfig.Rank = ADC_REGULAR_RANK_5;
  if (HAL_ADC_ConfigChannel(&hadc3, &sConfig) != HAL_OK)
  {
    Error_Handler();
  }

  /** Configure Regular Channel
  */
  sConfig.Channel = ADC_CHANNEL_5;
  sConfig.Rank = ADC_REGULAR_RANK_6;
  if (HAL_ADC_ConfigChannel(&hadc3, &sConfig) != HAL_OK)
  {
    Error_Handler();
  }

  /** Configure Regular Channel
  */
  sConfig.Channel = ADC_CHANNEL_6;
  sConfig.Rank = ADC_REGULAR_RANK_7;
  if (HAL_ADC_ConfigChannel(&hadc3, &sConfig) != HAL_OK)
  {
    Error_Handler();
  }

  /** Configure Regular Channel
  */
  sConfig.Channel = ADC_CHANNEL_7;
  sConfig.Rank = ADC_REGULAR_RANK_8;
  if (HAL_ADC_ConfigChannel(&hadc3, &sConfig) != HAL_OK)
  {
    Error_Handler();
  }

  /** Configure Regular Channel
  */
  sConfig.Channel = ADC_CHANNEL_8;
  sConfig.Rank = ADC_REGULAR_RANK_9;
  if (HAL_ADC_ConfigChannel(&hadc3, &sConfig) != HAL_OK)
  {
    Error_Handler();
  }

  /** Configure Regular Channel
  */
  sConfig.Channel = ADC_CHANNEL_9;
  sConfig.Rank = ADC_REGULAR_RANK_10;
  if (HAL_ADC_ConfigChannel(&hadc3, &sConfig) != HAL_OK)
  {
    Error_Handler();
  }

  /** Configure Regular Channel
  */
  sConfig.Channel = ADC_CHANNEL_10;
  sConfig.Rank = ADC_REGULAR_RANK_11;
  if (HAL_ADC_ConfigChannel(&hadc3, &sConfig) != HAL_OK)
  {
    Error_Handler();
  }

}

static void MX_COMP2_Init(void)
{

  hcomp2.Instance = COMP2;
  hcomp2.Init.InvertingInput = COMP_INPUT_MINUS_IO2;
  hcomp2.Init.NonInvertingInput = COMP_INPUT_PLUS_IO2;
  hcomp2.Init.OutputPol = COMP_OUTPUTPOL_NONINVERTED;
  hcomp2.Init.Hysteresis = COMP_HYSTERESIS_NONE;
  hcomp2.Init.BlankingSrce = COMP_BLANKINGSRC_NONE;
  hcomp2.Init.Mode = COMP_POWERMODE_HIGHSPEED;
  hcomp2.Init.WindowMode = COMP_WINDOWMODE_DISABLE;
  hcomp2.Init.TriggerMode = COMP_TRIGGERMODE_NONE;
  if (HAL_COMP_Init(&hcomp2) != HAL_OK)
  {
    Error_Handler();
  }

}

static void MX_ETH_Init(void)
{

   static uint8_t MACAddr[6];

  heth.Instance = ETH;
  MACAddr[0] = 0x00;
  MACAddr[1] = 0x80;
  MACAddr[2] = 0xE1;
  MACAddr[3] = 0x00;
  MACAddr[4] = 0x00;
  MACAddr[5] = 0x00;
  heth.Init.MACAddr = &MACAddr[0];
  heth.Init.MediaInterface = HAL_ETH_RMII_MODE;
  heth.Init.TxDesc = DMATxDscrTab;
  heth.Init.RxDesc = DMARxDscrTab;
  heth.Init.RxBuffLen = 1524;

  if (HAL_ETH_Init(&heth) != HAL_OK)
  {
    Error_Handler();
  }

  memset(&TxConfig, 0 , sizeof(ETH_TxPacketConfig));
  TxConfig.Attributes = ETH_TX_PACKETS_FEATURES_CSUM | ETH_TX_PACKETS_FEATURES_CRCPAD;
  TxConfig.ChecksumCtrl = ETH_CHECKSUM_IPHDR_PAYLOAD_INSERT_PHDR_CALC;
  TxConfig.CRCPadCtrl = ETH_CRC_PAD_INSERT;

}

static void MX_LPUART1_UART_Init(void)
{

  hlpuart1.Instance = LPUART1;
  hlpuart1.Init.BaudRate = 209700;
  hlpuart1.Init.WordLength = UART_WORDLENGTH_8B;
  hlpuart1.Init.StopBits = UART_STOPBITS_1;
  hlpuart1.Init.Parity = UART_PARITY_NONE;
  hlpuart1.Init.Mode = UART_MODE_TX_RX;
  hlpuart1.Init.HwFlowCtl = UART_HWCONTROL_NONE;
  hlpuart1.Init.OneBitSampling = UART_ONE_BIT_SAMPLE_DISABLE;
  hlpuart1.Init.ClockPrescaler = UART_PRESCALER_DIV1;
  hlpuart1.AdvancedInit.AdvFeatureInit = UART_ADVFEATURE_NO_INIT;
  hlpuart1.FifoMode = UART_FIFOMODE_DISABLE;
  if (HAL_UART_Init(&hlpuart1) != HAL_OK)
  {
    Error_Handler();
  }
  if (HAL_UARTEx_SetTxFifoThreshold(&hlpuart1, UART_TXFIFO_THRESHOLD_1_8) != HAL_OK)
  {
    Error_Handler();
  }
  if (HAL_UARTEx_SetRxFifoThreshold(&hlpuart1, UART_RXFIFO_THRESHOLD_1_8) != HAL_OK)
  {
    Error_Handler();
  }
  if (HAL_UARTEx_DisableFifoMode(&hlpuart1) != HAL_OK)
  {
    Error_Handler();
  }

}

static void MX_USART3_UART_Init(void)
{

  huart3.Instance = USART3;
  huart3.Init.BaudRate = 6875000;
  huart3.Init.WordLength = UART_WORDLENGTH_8B;
  huart3.Init.StopBits = UART_STOPBITS_1;
  huart3.Init.Parity = UART_PARITY_NONE;
  huart3.Init.Mode = UART_MODE_TX_RX;
  huart3.Init.HwFlowCtl = UART_HWCONTROL_NONE;
  huart3.Init.OverSampling = UART_OVERSAMPLING_16;
  huart3.Init.OneBitSampling = UART_ONE_BIT_SAMPLE_DISABLE;
  huart3.Init.ClockPrescaler = UART_PRESCALER_DIV1;
  huart3.AdvancedInit.AdvFeatureInit = UART_ADVFEATURE_NO_INIT;
  if (HAL_UART_Init(&huart3) != HAL_OK)
  {
    Error_Handler();
  }
  if (HAL_UARTEx_SetTxFifoThreshold(&huart3, UART_TXFIFO_THRESHOLD_1_8) != HAL_OK)
  {
    Error_Handler();
  }
  if (HAL_UARTEx_SetRxFifoThreshold(&huart3, UART_RXFIFO_THRESHOLD_1_8) != HAL_OK)
  {
    Error_Handler();
  }
  if (HAL_UARTEx_DisableFifoMode(&huart3) != HAL_OK)
  {
    Error_Handler();
  }

}

static void MX_TIM1_Init(void)
{

  TIM_MasterConfigTypeDef sMasterConfig = {0};
  TIM_OC_InitTypeDef sConfigOC = {0};
  TIM_BreakDeadTimeConfigTypeDef sBreakDeadTimeConfig = {0};

  htim1.Instance = TIM1;
  htim1.Init.Prescaler = 0;
  htim1.Init.CounterMode = TIM_COUNTERMODE_UP;
  htim1.Init.Period = 3240;
  htim1.Init.ClockDivision = TIM_CLOCKDIVISION_DIV1;
  htim1.Init.RepetitionCounter = 0;
  htim1.Init.AutoReloadPreload = TIM_AUTORELOAD_PRELOAD_DISABLE;
  if (HAL_TIM_PWM_Init(&htim1) != HAL_OK)
  {
    Error_Handler();
  }
  sMasterConfig.MasterOutputTrigger = TIM_TRGO_RESET;
  sMasterConfig.MasterOutputTrigger2 = TIM_TRGO2_RESET;
  sMasterConfig.MasterSlaveMode = TIM_MASTERSLAVEMODE_DISABLE;
  if (HAL_TIMEx_MasterConfigSynchronization(&htim1, &sMasterConfig) != HAL_OK)
  {
    Error_Handler();
  }
  sConfigOC.OCMode = TIM_OCMODE_PWM1;
  sConfigOC.Pulse = 1620;
  sConfigOC.OCPolarity = TIM_OCPOLARITY_LOW;
  sConfigOC.OCNPolarity = TIM_OCNPOLARITY_LOW;
  sConfigOC.OCFastMode = TIM_OCFAST_DISABLE;
  sConfigOC.OCIdleState = TIM_OCIDLESTATE_SET;
  sConfigOC.OCNIdleState = TIM_OCNIDLESTATE_SET;
  if (HAL_TIM_PWM_ConfigChannel(&htim1, &sConfigOC, TIM_CHANNEL_1) != HAL_OK)
  {
    Error_Handler();
  }
  sBreakDeadTimeConfig.OffStateRunMode = TIM_OSSR_DISABLE;
  sBreakDeadTimeConfig.OffStateIDLEMode = TIM_OSSI_DISABLE;
  sBreakDeadTimeConfig.LockLevel = TIM_LOCKLEVEL_OFF;
  sBreakDeadTimeConfig.DeadTime = 0xFF;
  sBreakDeadTimeConfig.BreakState = TIM_BREAK_DISABLE;
  sBreakDeadTimeConfig.BreakPolarity = TIM_BREAKPOLARITY_HIGH;
  sBreakDeadTimeConfig.BreakFilter = 0;
  sBreakDeadTimeConfig.Break2State = TIM_BREAK2_DISABLE;
  sBreakDeadTimeConfig.Break2Polarity = TIM_BREAK2POLARITY_HIGH;
  sBreakDeadTimeConfig.Break2Filter = 0;
  sBreakDeadTimeConfig.AutomaticOutput = TIM_AUTOMATICOUTPUT_DISABLE;
  if (HAL_TIMEx_ConfigBreakDeadTime(&htim1, &sBreakDeadTimeConfig) != HAL_OK)
  {
    Error_Handler();
  }
  HAL_TIM_MspPostInit(&htim1);

}

static void MX_TIM2_Init(void)
{

  TIM_MasterConfigTypeDef sMasterConfig = {0};
  TIM_OC_InitTypeDef sConfigOC = {0};

  htim2.Instance = TIM2;
  htim2.Init.Prescaler = 0;
  htim2.Init.CounterMode = TIM_COUNTERMODE_UP;
  htim2.Init.Period = 4294967295;
  htim2.Init.ClockDivision = TIM_CLOCKDIVISION_DIV1;
  htim2.Init.AutoReloadPreload = TIM_AUTORELOAD_PRELOAD_DISABLE;
  if (HAL_TIM_PWM_Init(&htim2) != HAL_OK)
  {
    Error_Handler();
  }
  sMasterConfig.MasterOutputTrigger = TIM_TRGO_RESET;
  sMasterConfig.MasterSlaveMode = TIM_MASTERSLAVEMODE_DISABLE;
  if (HAL_TIMEx_MasterConfigSynchronization(&htim2, &sMasterConfig) != HAL_OK)
  {
    Error_Handler();
  }
  sConfigOC.OCMode = TIM_OCMODE_PWM1;
  sConfigOC.Pulse = 0;
  sConfigOC.OCPolarity = TIM_OCPOLARITY_HIGH;
  sConfigOC.OCFastMode = TIM_OCFAST_DISABLE;
  if (HAL_TIM_PWM_ConfigChannel(&htim2, &sConfigOC, TIM_CHANNEL_1) != HAL_OK)
  {
    Error_Handler();
  }
  HAL_TIM_MspPostInit(&htim2);

}

static void MX_TIM3_Init(void)
{

  TIM_MasterConfigTypeDef sMasterConfig = {0};
  TIM_IC_InitTypeDef sConfigIC = {0};

  htim3.Instance = TIM3;
  htim3.Init.Prescaler = 0;
  htim3.Init.CounterMode = TIM_COUNTERMODE_UP;
  htim3.Init.Period = 65535;
  htim3.Init.ClockDivision = TIM_CLOCKDIVISION_DIV1;
  htim3.Init.AutoReloadPreload = TIM_AUTORELOAD_PRELOAD_DISABLE;
  if (HAL_TIM_IC_Init(&htim3) != HAL_OK)
  {
    Error_Handler();
  }
  sMasterConfig.MasterOutputTrigger = TIM_TRGO_RESET;
  sMasterConfig.MasterSlaveMode = TIM_MASTERSLAVEMODE_DISABLE;
  if (HAL_TIMEx_MasterConfigSynchronization(&htim3, &sMasterConfig) != HAL_OK)
  {
    Error_Handler();
  }
  sConfigIC.ICPolarity = TIM_INPUTCHANNELPOLARITY_RISING;
  sConfigIC.ICSelection = TIM_ICSELECTION_DIRECTTI;
  sConfigIC.ICPrescaler = TIM_ICPSC_DIV1;
  sConfigIC.ICFilter = 0;
  if (HAL_TIM_IC_ConfigChannel(&htim3, &sConfigIC, TIM_CHANNEL_1) != HAL_OK)
  {
    Error_Handler();
  }

}

static void MX_TIM4_Init(void)
{

  TIM_MasterConfigTypeDef sMasterConfig = {0};
  TIM_OC_InitTypeDef sConfigOC = {0};

  htim4.Instance = TIM4;
  htim4.Init.Prescaler = 0;
  htim4.Init.CounterMode = TIM_COUNTERMODE_UP;
  htim4.Init.Period = 65535;
  htim4.Init.ClockDivision = TIM_CLOCKDIVISION_DIV1;
  htim4.Init.AutoReloadPreload = TIM_AUTORELOAD_PRELOAD_DISABLE;
  if (HAL_TIM_PWM_Init(&htim4) != HAL_OK)
  {
    Error_Handler();
  }
  sMasterConfig.MasterOutputTrigger = TIM_TRGO_RESET;
  sMasterConfig.MasterSlaveMode = TIM_MASTERSLAVEMODE_DISABLE;
  if (HAL_TIMEx_MasterConfigSynchronization(&htim4, &sMasterConfig) != HAL_OK)
  {
    Error_Handler();
  }
  sConfigOC.OCMode = TIM_OCMODE_PWM1;
  sConfigOC.Pulse = 0;
  sConfigOC.OCPolarity = TIM_OCPOLARITY_HIGH;
  sConfigOC.OCFastMode = TIM_OCFAST_DISABLE;
  if (HAL_TIM_PWM_ConfigChannel(&htim4, &sConfigOC, TIM_CHANNEL_1) != HAL_OK)
  {
    Error_Handler();
  }
  HAL_TIM_MspPostInit(&htim4);

}

static void MX_TIM15_Init(void)
{

  TIM_MasterConfigTypeDef sMasterConfig = {0};
  TIM_IC_InitTypeDef sConfigIC = {0};

  htim15.Instance = TIM15;
  htim15.Init.Prescaler = 0;
  htim15.Init.CounterMode = TIM_COUNTERMODE_UP;
  htim15.Init.Period = 65535;
  htim15.Init.ClockDivision = TIM_CLOCKDIVISION_DIV1;
  htim15.Init.RepetitionCounter = 0;
  htim15.Init.AutoReloadPreload = TIM_AUTORELOAD_PRELOAD_DISABLE;
  if (HAL_TIM_IC_Init(&htim15) != HAL_OK)
  {
    Error_Handler();
  }
  sMasterConfig.MasterOutputTrigger = TIM_TRGO_RESET;
  sMasterConfig.MasterSlaveMode = TIM_MASTERSLAVEMODE_DISABLE;
  if (HAL_TIMEx_MasterConfigSynchronization(&htim15, &sMasterConfig) != HAL_OK)
  {
    Error_Handler();
  }
  sConfigIC.ICPolarity = TIM_INPUTCHANNELPOLARITY_RISING;
  sConfigIC.ICSelection = TIM_ICSELECTION_DIRECTTI;
  sConfigIC.ICPrescaler = TIM_ICPSC_DIV1;
  sConfigIC.ICFilter = 0;
  if (HAL_TIM_IC_ConfigChannel(&htim15, &sConfigIC, TIM_CHANNEL_1) != HAL_OK)
  {
    Error_Handler();
  }

}

static void MX_TIM24_Init(void)
{

  TIM_ClockConfigTypeDef sClockSourceConfig = {0};
  TIM_MasterConfigTypeDef sMasterConfig = {0};

  htim24.Instance = TIM24;
  htim24.Init.Prescaler = 275 - 1;
  htim24.Init.CounterMode = TIM_COUNTERMODE_UP;
  htim24.Init.Period = 4294967295;
  htim24.Init.ClockDivision = TIM_CLOCKDIVISION_DIV1;
  htim24.Init.AutoReloadPreload = TIM_AUTORELOAD_PRELOAD_ENABLE;
  if (HAL_TIM_Base_Init(&htim24) != HAL_OK)
  {
    Error_Handler();
  }
  sClockSourceConfig.ClockSource = TIM_CLOCKSOURCE_INTERNAL;
  if (HAL_TIM_ConfigClockSource(&htim24, &sClockSourceConfig) != HAL_OK)
  {
    Error_Handler();
  }
  sMasterConfig.MasterOutputTrigger = TIM_TRGO_RESET;
  sMasterConfig.MasterSlaveMode = TIM_MASTERSLAVEMODE_DISABLE;
  if (HAL_TIMEx_MasterConfigSynchronization(&htim24, &sMasterConfig) != HAL_OK)
  {
    Error_Handler();
  }

}

static void MX_USB_OTG_HS_USB_Init(void)
{

}

static void MX_DMA_Init(void)
{

  /* DMA controller clock enable */
  __HAL_RCC_DMA1_CLK_ENABLE();

  /* DMA interrupt init */
  /* DMA1_Stream1_IRQn interrupt configuration */
  HAL_NVIC_SetPriority(DMA1_Stream1_IRQn, 0, 0);
  HAL_NVIC_EnableIRQ(DMA1_Stream1_IRQn);
  /* DMA1_Stream2_IRQn interrupt configuration */
  HAL_NVIC_SetPriority(DMA1_Stream2_IRQn, 0, 0);
  HAL_NVIC_EnableIRQ(DMA1_Stream2_IRQn);

}

static void MX_GPIO_Init(void)
{
  GPIO_InitTypeDef GPIO_InitStruct = {0};

  /* GPIO Ports Clock Enable */
  __HAL_RCC_GPIOE_CLK_ENABLE();
  __HAL_RCC_GPIOC_CLK_ENABLE();
  __HAL_RCC_GPIOF_CLK_ENABLE();
  __HAL_RCC_GPIOH_CLK_ENABLE();
  __HAL_RCC_GPIOA_CLK_ENABLE();
  __HAL_RCC_GPIOB_CLK_ENABLE();
  __HAL_RCC_GPIOG_CLK_ENABLE();
  __HAL_RCC_GPIOD_CLK_ENABLE();

  /*Configure GPIO pin Output Level */
  HAL_GPIO_WritePin(GPIOB, LED_GREEN_Pin|LINE_DRIVER1_ENABLE_Pin|LINE_DRIVER2_ENABLE_Pin, GPIO_PIN_SET);

  /*Configure GPIO pin Output Level */
  HAL_GPIO_WritePin(TEST_OUTPUT_GPIO_Port, TEST_OUTPUT_Pin, GPIO_PIN_RESET);

  /*Configure GPIO pin Output Level */
  HAL_GPIO_WritePin(LED_RED_GPIO_Port, LED_RED_Pin, GPIO_PIN_RESET);

  /*Configure GPIO pin Output Level */
  HAL_GPIO_WritePin(OUT_3V3_SWITCH_GPIO_Port, OUT_3V3_SWITCH_Pin, GPIO_PIN_SET);

  /*Configure GPIO pin Output Level */
  HAL_GPIO_WritePin(LED_ACTIVE_GPIO_Port, LED_ACTIVE_Pin, GPIO_PIN_SET);

  /*Configure GPIO pin Output Level */
  HAL_GPIO_WritePin(LED_YELLOW_GPIO_Port, LED_YELLOW_Pin, GPIO_PIN_RESET);

  /*Configure GPIO pin : B1_Pin */
  GPIO_InitStruct.Pin = B1_Pin;
  GPIO_InitStruct.Mode = GPIO_MODE_INPUT;
  GPIO_InitStruct.Pull = GPIO_NOPULL;
  HAL_GPIO_Init(B1_GPIO_Port, &GPIO_InitStruct);

  /*Configure GPIO pins : LED_GREEN_Pin LINE_DRIVER1_ENABLE_Pin LINE_DRIVER2_ENABLE_Pin LED_RED_Pin */
  GPIO_InitStruct.Pin = LED_GREEN_Pin|LINE_DRIVER1_ENABLE_Pin|LINE_DRIVER2_ENABLE_Pin|LED_RED_Pin;
  GPIO_InitStruct.Mode = GPIO_MODE_OUTPUT_PP;
  GPIO_InitStruct.Pull = GPIO_NOPULL;
  GPIO_InitStruct.Speed = GPIO_SPEED_FREQ_LOW;
  HAL_GPIO_Init(GPIOB, &GPIO_InitStruct);

  /*Configure GPIO pin : OUT_500V_ENABLE_Pin */
  GPIO_InitStruct.Pin = OUT_500V_ENABLE_Pin;
  GPIO_InitStruct.Mode = GPIO_MODE_INPUT;
  GPIO_InitStruct.Pull = GPIO_NOPULL;
  HAL_GPIO_Init(OUT_500V_ENABLE_GPIO_Port, &GPIO_InitStruct);

  /*Configure GPIO pin : TEST_OUTPUT_Pin */
  GPIO_InitStruct.Pin = TEST_OUTPUT_Pin;
  GPIO_InitStruct.Mode = GPIO_MODE_OUTPUT_PP;
  GPIO_InitStruct.Pull = GPIO_NOPULL;
  GPIO_InitStruct.Speed = GPIO_SPEED_FREQ_LOW;
  HAL_GPIO_Init(TEST_OUTPUT_GPIO_Port, &GPIO_InitStruct);

  /*Configure GPIO pin : TURN_PLASMA_ON_Pin */
  GPIO_InitStruct.Pin = TURN_PLASMA_ON_Pin;
  GPIO_InitStruct.Mode = GPIO_MODE_INPUT;
  GPIO_InitStruct.Pull = GPIO_NOPULL;
  HAL_GPIO_Init(TURN_PLASMA_ON_GPIO_Port, &GPIO_InitStruct);

  /*Configure GPIO pin : INP_COMP_IRQ_Pin */
  GPIO_InitStruct.Pin = INP_COMP_IRQ_Pin;
  GPIO_InitStruct.Mode = GPIO_MODE_IT_RISING;
  GPIO_InitStruct.Pull = GPIO_NOPULL;
  HAL_GPIO_Init(INP_COMP_IRQ_GPIO_Port, &GPIO_InitStruct);

  /*Configure GPIO pin : POWER_OFF_IRQ_Pin */
  GPIO_InitStruct.Pin = POWER_OFF_IRQ_Pin;
  GPIO_InitStruct.Mode = GPIO_MODE_IT_FALLING;
  GPIO_InitStruct.Pull = GPIO_NOPULL;
  HAL_GPIO_Init(POWER_OFF_IRQ_GPIO_Port, &GPIO_InitStruct);

  /*Configure GPIO pin : USB_FS_OVCR_Pin */
  GPIO_InitStruct.Pin = USB_FS_OVCR_Pin;
  GPIO_InitStruct.Mode = GPIO_MODE_IT_RISING;
  GPIO_InitStruct.Pull = GPIO_NOPULL;
  HAL_GPIO_Init(USB_FS_OVCR_GPIO_Port, &GPIO_InitStruct);

  /*Configure GPIO pin : USB_FS_VBUS_Pin */
  GPIO_InitStruct.Pin = USB_FS_VBUS_Pin;
  GPIO_InitStruct.Mode = GPIO_MODE_INPUT;
  GPIO_InitStruct.Pull = GPIO_NOPULL;
  HAL_GPIO_Init(USB_FS_VBUS_GPIO_Port, &GPIO_InitStruct);

  /*Configure GPIO pin : USB_FS_ID_Pin */
  GPIO_InitStruct.Pin = USB_FS_ID_Pin;
  GPIO_InitStruct.Mode = GPIO_MODE_AF_PP;
  GPIO_InitStruct.Pull = GPIO_NOPULL;
  GPIO_InitStruct.Speed = GPIO_SPEED_FREQ_LOW;
  GPIO_InitStruct.Alternate = GPIO_AF10_OTG1_HS;
  HAL_GPIO_Init(USB_FS_ID_GPIO_Port, &GPIO_InitStruct);

  /*Configure GPIO pin : OUT_3V3_SWITCH_Pin */
  GPIO_InitStruct.Pin = OUT_3V3_SWITCH_Pin;
  GPIO_InitStruct.Mode = GPIO_MODE_OUTPUT_PP;
  GPIO_InitStruct.Pull = GPIO_NOPULL;
  GPIO_InitStruct.Speed = GPIO_SPEED_FREQ_LOW;
  HAL_GPIO_Init(OUT_3V3_SWITCH_GPIO_Port, &GPIO_InitStruct);

  /*Configure GPIO pin : OUT_15V_ENABLE_Pin */
  GPIO_InitStruct.Pin = OUT_15V_ENABLE_Pin;
  GPIO_InitStruct.Mode = GPIO_MODE_INPUT;
  GPIO_InitStruct.Pull = GPIO_NOPULL;
  HAL_GPIO_Init(OUT_15V_ENABLE_GPIO_Port, &GPIO_InitStruct);

  /*Configure GPIO pins : LED_ACTIVE_Pin LED_YELLOW_Pin */
  GPIO_InitStruct.Pin = LED_ACTIVE_Pin|LED_YELLOW_Pin;
  GPIO_InitStruct.Mode = GPIO_MODE_OUTPUT_PP;
  GPIO_InitStruct.Pull = GPIO_NOPULL;
  GPIO_InitStruct.Speed = GPIO_SPEED_FREQ_LOW;
  HAL_GPIO_Init(GPIOE, &GPIO_InitStruct);

  /* EXTI interrupt init*/
  HAL_NVIC_SetPriority(EXTI15_10_IRQn, 0, 0);
  HAL_NVIC_EnableIRQ(EXTI15_10_IRQn);

}

void Error_Handler(void)
{
  __disable_irq();
  while (1)
  {
  }
}
